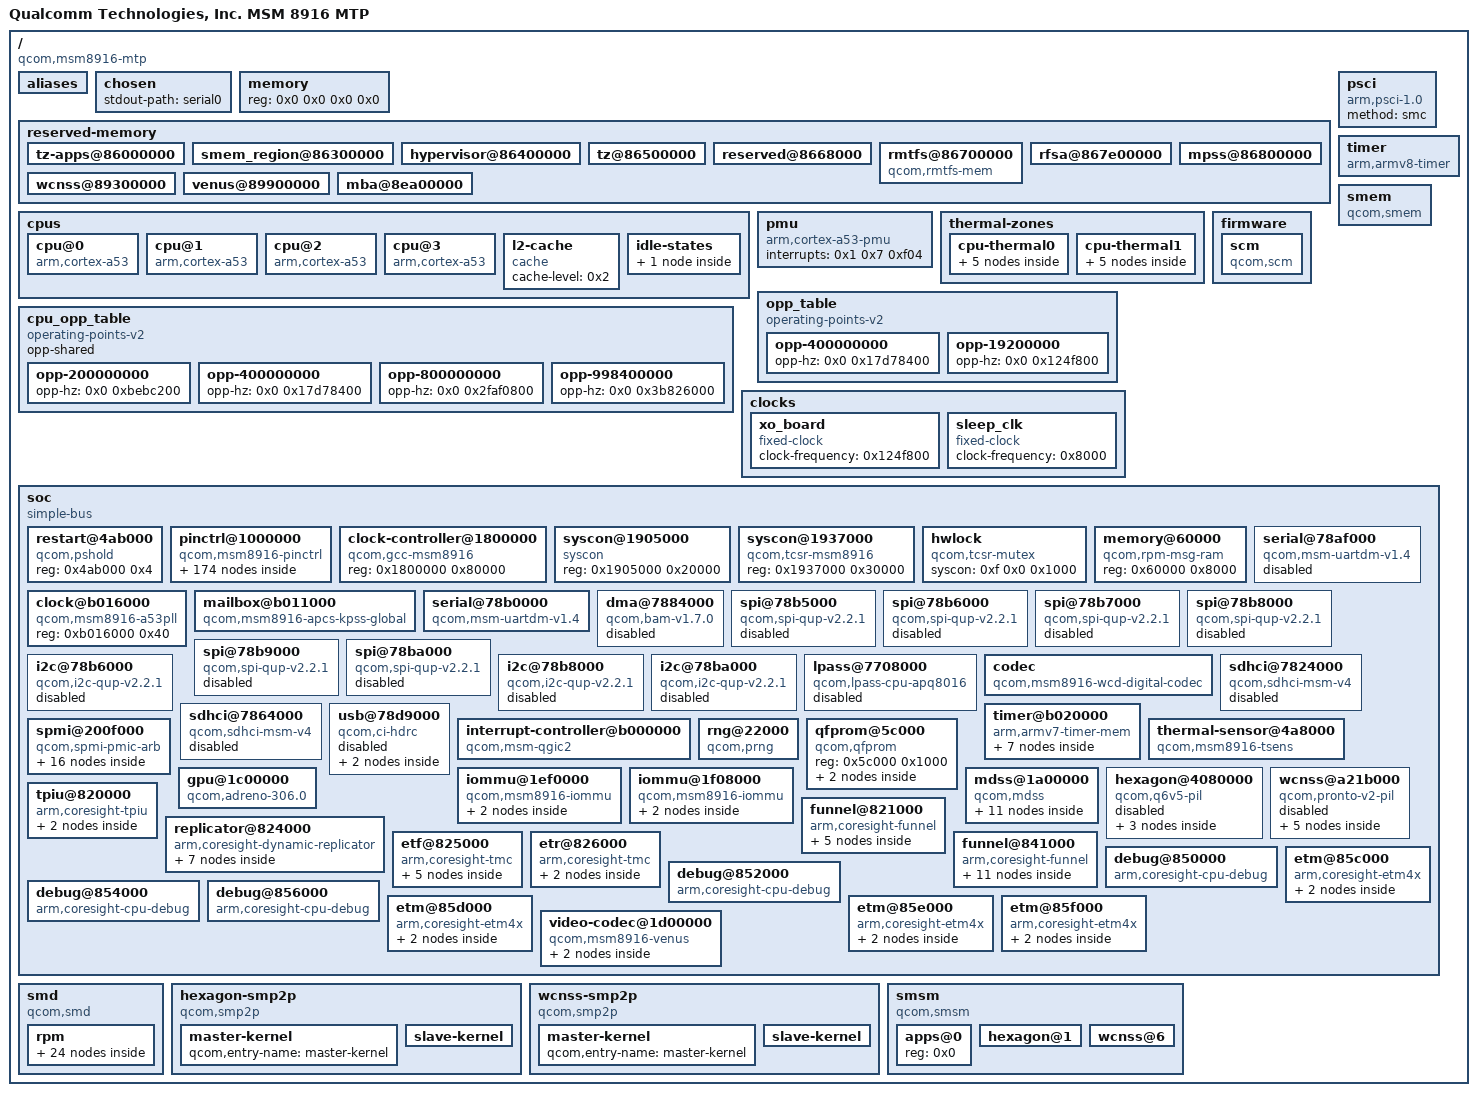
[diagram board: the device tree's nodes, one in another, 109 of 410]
/dts-v1/;

/ {
	model = "Qualcomm Technologies, Inc. MSM 8916 MTP";
	compatible = "qcom,msm8916-mtp", "qcom,msm8916-mtp/1", "qcom,msm8916", "qcom,mtp";
	interrupt-parent = <0x1>;
	#address-cells = <0x2>;
	#size-cells = <0x2>;

	aliases {
		sdhc1 = "/soc/sdhci@7824000";
		sdhc2 = "/soc/sdhci@7864000";
		serial0 = "/soc/serial@78b0000";
		usid0 = "/soc/spmi@200f000/pm8916@0";
	};

	chosen {
		stdout-path = "serial0";
	};

	memory {
		device_type = "memory";
		reg = <0x0 0x0 0x0 0x0>;
	};

	reserved-memory {
		#address-cells = <0x2>;
		#size-cells = <0x2>;
		ranges;

		tz-apps@86000000 {
			reg = <0x0 0x86000000 0x0 0x300000>;
			no-map;
		};

		smem_region@86300000 {
			reg = <0x0 0x86300000 0x0 0x100000>;
			no-map;
			phandle = <0xa>;
		};

		hypervisor@86400000 {
			reg = <0x0 0x86400000 0x0 0x100000>;
			no-map;
		};

		tz@86500000 {
			reg = <0x0 0x86500000 0x0 0x180000>;
			no-map;
		};

		reserved@8668000 {
			reg = <0x0 0x86680000 0x0 0x80000>;
			no-map;
		};

		rmtfs@86700000 {
			compatible = "qcom,rmtfs-mem";
			reg = <0x0 0x86700000 0x0 0xe0000>;
			no-map;
			qcom,client-id = <0x1>;
		};

		rfsa@867e00000 {
			reg = <0x0 0x867e0000 0x0 0x20000>;
			no-map;
		};

		mpss@86800000 {
			reg = <0x0 0x86800000 0x0 0x2b00000>;
			no-map;
			phandle = <0x3d>;
		};

		wcnss@89300000 {
			reg = <0x0 0x89300000 0x0 0x600000>;
			no-map;
			phandle = <0x3e>;
		};

		venus@89900000 {
			reg = <0x0 0x89900000 0x0 0x600000>;
			no-map;
			phandle = <0x5c>;
		};

		mba@8ea00000 {
			no-map;
			reg = <0x0 0x8ea00000 0x0 0x100000>;
			phandle = <0x3c>;
		};
	};

	cpus {
		#address-cells = <0x1>;
		#size-cells = <0x0>;

		cpu@0 {
			device_type = "cpu";
			compatible = "arm,cortex-a53", "arm,armv8";
			reg = <0x0>;
			next-level-cache = <0x2>;
			enable-method = "psci";
			cpu-idle-states = <0x3>;
			clocks = <0x4>;
			operating-points-v2 = <0x5>;
			#cooling-cells = <0x2>;
			phandle = <0x8>;
		};

		cpu@1 {
			device_type = "cpu";
			compatible = "arm,cortex-a53", "arm,armv8";
			reg = <0x1>;
			next-level-cache = <0x2>;
			enable-method = "psci";
			cpu-idle-states = <0x3>;
			clocks = <0x4>;
			operating-points-v2 = <0x5>;
			#cooling-cells = <0x2>;
			phandle = <0x55>;
		};

		cpu@2 {
			device_type = "cpu";
			compatible = "arm,cortex-a53", "arm,armv8";
			reg = <0x2>;
			next-level-cache = <0x2>;
			enable-method = "psci";
			cpu-idle-states = <0x3>;
			clocks = <0x4>;
			operating-points-v2 = <0x5>;
			#cooling-cells = <0x2>;
			phandle = <0x56>;
		};

		cpu@3 {
			device_type = "cpu";
			compatible = "arm,cortex-a53", "arm,armv8";
			reg = <0x3>;
			next-level-cache = <0x2>;
			enable-method = "psci";
			cpu-idle-states = <0x3>;
			clocks = <0x4>;
			operating-points-v2 = <0x5>;
			#cooling-cells = <0x2>;
			phandle = <0x57>;
		};

		l2-cache {
			compatible = "cache";
			cache-level = <0x2>;
			phandle = <0x2>;
		};

		idle-states {

			spc {
				compatible = "arm,idle-state";
				arm,psci-suspend-param = <0x40000002>;
				entry-latency-us = <0x82>;
				exit-latency-us = <0x96>;
				min-residency-us = <0x7d0>;
				local-timer-stop;
				phandle = <0x3>;
			};
		};
	};

	psci {
		compatible = "arm,psci-1.0";
		method = "smc";
	};

	pmu {
		compatible = "arm,cortex-a53-pmu";
		interrupts = <0x1 0x7 0xf04>;
	};

	thermal-zones {

		cpu-thermal0 {
			polling-delay-passive = <0xfa>;
			polling-delay = <0x3e8>;
			thermal-sensors = <0x6 0x4>;

			trips {

				trip0 {
					temperature = <0x124f8>;
					hysteresis = <0x7d0>;
					type = "passive";
					phandle = <0x7>;
				};

				trip1 {
					temperature = <0x1adb0>;
					hysteresis = <0x7d0>;
					type = "critical";
					phandle = <0x5d>;
				};
			};

			cooling-maps {

				map0 {
					trip = <0x7>;
					cooling-device = <0x8 0xffffffff 0xffffffff>;
				};
			};
		};

		cpu-thermal1 {
			polling-delay-passive = <0xfa>;
			polling-delay = <0x3e8>;
			thermal-sensors = <0x6 0x3>;

			trips {

				trip0 {
					temperature = <0x124f8>;
					hysteresis = <0x7d0>;
					type = "passive";
					phandle = <0x9>;
				};

				trip1 {
					temperature = <0x1adb0>;
					hysteresis = <0x7d0>;
					type = "critical";
					phandle = <0x5e>;
				};
			};

			cooling-maps {

				map0 {
					trip = <0x9>;
					cooling-device = <0x8 0xffffffff 0xffffffff>;
				};
			};
		};
	};

	cpu_opp_table {
		compatible = "operating-points-v2";
		opp-shared;
		phandle = <0x5>;

		opp-200000000 {
			opp-hz = <0x0 0xbebc200>;
		};

		opp-400000000 {
			opp-hz = <0x0 0x17d78400>;
		};

		opp-800000000 {
			opp-hz = <0x0 0x2faf0800>;
		};

		opp-998400000 {
			opp-hz = <0x0 0x3b826000>;
		};
	};

	opp_table {
		compatible = "operating-points-v2";
		phandle = <0x2f>;

		opp-400000000 {
			opp-hz = <0x0 0x17d78400>;
		};

		opp-19200000 {
			opp-hz = <0x0 0x124f800>;
		};
	};

	timer {
		compatible = "arm,armv8-timer";
		interrupts = <0x1 0x2 0xf08 0x1 0x3 0xf08 0x1 0x4 0xf08 0x1 0x1 0xf08>;
	};

	clocks {

		xo_board {
			compatible = "fixed-clock";
			#clock-cells = <0x0>;
			clock-frequency = <0x124f800>;
			phandle = <0x26>;
		};

		sleep_clk {
			compatible = "fixed-clock";
			#clock-cells = <0x0>;
			clock-frequency = <0x8000>;
			phandle = <0x5f>;
		};
	};

	smem {
		compatible = "qcom,smem";
		memory-region = <0xa>;
		qcom,rpm-msg-ram = <0xb>;
		hwlocks = <0xc 0x3>;
	};

	firmware {

		scm {
			compatible = "qcom,scm";
			clocks = <0xd 0x68 0xd 0x67 0xd 0x66>;
			clock-names = "core", "bus", "iface";
			#reset-cells = <0x1>;
			qcom,dload-mode = <0xe 0x6100>;
			phandle = <0x38>;
		};
	};

	soc {
		#address-cells = <0x1>;
		#size-cells = <0x1>;
		ranges = <0x0 0x0 0x0 0xffffffff>;
		compatible = "simple-bus";
		phandle = <0x60>;

		restart@4ab000 {
			compatible = "qcom,pshold";
			reg = <0x4ab000 0x4>;
		};

		pinctrl@1000000 {
			compatible = "qcom,msm8916-pinctrl";
			reg = <0x1000000 0x300000>;
			interrupts = <0x0 0xd0 0x4>;
			gpio-controller;
			#gpio-cells = <0x2>;
			interrupt-controller;
			#interrupt-cells = <0x2>;
			phandle = <0x61>;

			blsp1_uart1_default {
				phandle = <0x62>;

				pinmux {
					function = "blsp_uart1";
					pins = "gpio0", "gpio1", "gpio2", "gpio3";
				};

				pinconf {
					pins = "gpio0", "gpio1", "gpio2", "gpio3";
					drive-strength = <0x10>;
					bias-disable;
				};
			};

			blsp1_uart1_sleep {
				phandle = <0x63>;

				pinmux {
					function = "gpio";
					pins = "gpio0", "gpio1", "gpio2", "gpio3";
				};

				pinconf {
					pins = "gpio0", "gpio1", "gpio2", "gpio3";
					drive-strength = <0x2>;
					bias-pull-down;
				};
			};

			blsp1_uart2_default {
				phandle = <0x12>;

				pinmux {
					function = "blsp_uart2";
					pins = "gpio4", "gpio5";
				};

				pinconf {
					pins = "gpio4", "gpio5";
					drive-strength = <0x10>;
					bias-disable;
				};
			};

			blsp1_uart2_sleep {
				phandle = <0x13>;

				pinmux {
					function = "gpio";
					pins = "gpio4", "gpio5";
				};

				pinconf {
					pins = "gpio4", "gpio5";
					drive-strength = <0x2>;
					bias-pull-down;
				};
			};

			spi1_default {
				phandle = <0x14>;

				pinmux {
					function = "blsp_spi1";
					pins = "gpio0", "gpio1", "gpio3";
				};

				pinmux_cs {
					function = "gpio";
					pins = "gpio2";
				};

				pinconf {
					pins = "gpio0", "gpio1", "gpio3";
					drive-strength = <0xc>;
					bias-disable;
				};

				pinconf_cs {
					pins = "gpio2";
					drive-strength = <0x10>;
					bias-disable;
					output-high;
				};
			};

			spi1_sleep {
				phandle = <0x15>;

				pinmux {
					function = "gpio";
					pins = "gpio0", "gpio1", "gpio2", "gpio3";
				};

				pinconf {
					pins = "gpio0", "gpio1", "gpio2", "gpio3";
					drive-strength = <0x2>;
					bias-pull-down;
				};
			};

			spi2_default {
				phandle = <0x16>;

				pinmux {
					function = "blsp_spi2";
					pins = "gpio4", "gpio5", "gpio7";
				};

				pinmux_cs {
					function = "gpio";
					pins = "gpio6";
				};

				pinconf {
					pins = "gpio4", "gpio5", "gpio7";
					drive-strength = <0xc>;
					bias-disable;
				};

				pinconf_cs {
					pins = "gpio6";
					drive-strength = <0x10>;
					bias-disable;
					output-high;
				};
			};

			spi2_sleep {
				phandle = <0x17>;

				pinmux {
					function = "gpio";
					pins = "gpio4", "gpio5", "gpio6", "gpio7";
				};

				pinconf {
					pins = "gpio4", "gpio5", "gpio6", "gpio7";
					drive-strength = <0x2>;
					bias-pull-down;
				};
			};

			spi3_default {
				phandle = <0x18>;

				pinmux {
					function = "blsp_spi3";
					pins = "gpio8", "gpio9", "gpio11";
				};

				pinmux_cs {
					function = "gpio";
					pins = "gpio10";
				};

				pinconf {
					pins = "gpio8", "gpio9", "gpio11";
					drive-strength = <0xc>;
					bias-disable;
				};

				pinconf_cs {
					pins = "gpio10";
					drive-strength = <0x10>;
					bias-disable;
					output-high;
				};
			};

			spi3_sleep {
				phandle = <0x19>;

				pinmux {
					function = "gpio";
					pins = "gpio8", "gpio9", "gpio10", "gpio11";
				};

				pinconf {
					pins = "gpio8", "gpio9", "gpio10", "gpio11";
					drive-strength = <0x2>;
					bias-pull-down;
				};
			};

			spi4_default {
				phandle = <0x1a>;

				pinmux {
					function = "blsp_spi4";
					pins = "gpio12", "gpio13", "gpio15";
				};

				pinmux_cs {
					function = "gpio";
					pins = "gpio14";
				};

				pinconf {
					pins = "gpio12", "gpio13", "gpio15";
					drive-strength = <0xc>;
					bias-disable;
				};

				pinconf_cs {
					pins = "gpio14";
					drive-strength = <0x10>;
					bias-disable;
					output-high;
				};
			};

			spi4_sleep {
				phandle = <0x1b>;

				pinmux {
					function = "gpio";
					pins = "gpio12", "gpio13", "gpio14", "gpio15";
				};

				pinconf {
					pins = "gpio12", "gpio13", "gpio14", "gpio15";
					drive-strength = <0x2>;
					bias-pull-down;
				};
			};

			spi5_default {
				phandle = <0x1c>;

				pinmux {
					function = "blsp_spi5";
					pins = "gpio16", "gpio17", "gpio19";
				};

				pinmux_cs {
					function = "gpio";
					pins = "gpio18";
				};

				pinconf {
					pins = "gpio16", "gpio17", "gpio19";
					drive-strength = <0xc>;
					bias-disable;
				};

				pinconf_cs {
					pins = "gpio18";
					drive-strength = <0x10>;
					bias-disable;
					output-high;
				};
			};

			spi5_sleep {
				phandle = <0x1d>;

				pinmux {
					function = "gpio";
					pins = "gpio16", "gpio17", "gpio18", "gpio19";
				};

				pinconf {
					pins = "gpio16", "gpio17", "gpio18", "gpio19";
					drive-strength = <0x2>;
					bias-pull-down;
				};
			};

			spi6_default {
				phandle = <0x1e>;

				pinmux {
					function = "blsp_spi6";
					pins = "gpio20", "gpio21", "gpio23";
				};

				pinmux_cs {
					function = "gpio";
					pins = "gpio22";
				};

				pinconf {
					pins = "gpio20", "gpio21", "gpio23";
					drive-strength = <0xc>;
					bias-disable;
				};

				pinconf_cs {
					pins = "gpio22";
					drive-strength = <0x10>;
					bias-disable;
					output-high;
				};
			};

			spi6_sleep {
				phandle = <0x1f>;

				pinmux {
					function = "gpio";
					pins = "gpio20", "gpio21", "gpio22", "gpio23";
				};

				pinconf {
					pins = "gpio20", "gpio21", "gpio22", "gpio23";
					drive-strength = <0x2>;
					bias-pull-down;
				};
			};

			i2c2_default {
				phandle = <0x20>;

				pinmux {
					function = "blsp_i2c2";
					pins = "gpio6", "gpio7";
				};

				pinconf {
					pins = "gpio6", "gpio7";
					drive-strength = <0x10>;
					bias-disable;
				};
			};

			i2c2_sleep {
				phandle = <0x21>;

				pinmux {
					function = "gpio";
					pins = "gpio6", "gpio7";
				};

				pinconf {
					pins = "gpio6", "gpio7";
					drive-strength = <0x2>;
					bias-disable;
				};
			};

			i2c4_default {
				phandle = <0x22>;

				pinmux {
					function = "blsp_i2c4";
					pins = "gpio14", "gpio15";
				};

				pinconf {
					pins = "gpio14", "gpio15";
					drive-strength = <0x10>;
					bias-disable;
				};
			};

			i2c4_sleep {
				phandle = <0x23>;

				pinmux {
					function = "gpio";
					pins = "gpio14", "gpio15";
				};

				pinconf {
					pins = "gpio14", "gpio15";
					drive-strength = <0x2>;
					bias-disable;
				};
			};

			i2c6_default {
				phandle = <0x24>;

				pinmux {
					function = "blsp_i2c6";
					pins = "gpio22", "gpio23";
				};

				pinconf {
					pins = "gpio22", "gpio23";
					drive-strength = <0x10>;
					bias-disable;
				};
			};

			i2c6_sleep {
				phandle = <0x25>;

				pinmux {
					function = "gpio";
					pins = "gpio22", "gpio23";
				};

				pinconf {
					pins = "gpio22", "gpio23";
					drive-strength = <0x2>;
					bias-disable;
				};
			};

			pmx_sdc1_clk {

				clk_on {
					phandle = <0x64>;

					pinmux {
						pins = "sdc1_clk";
					};

					pinconf {
						pins = "sdc1_clk";
						bias-disable;
						drive-strength = <0x10>;
					};
				};

				clk_off {
					phandle = <0x65>;

					pinmux {
						pins = "sdc1_clk";
					};

					pinconf {
						pins = "sdc1_clk";
						bias-disable;
						drive-strength = <0x2>;
					};
				};
			};

			pmx_sdc1_cmd {

				cmd_on {
					phandle = <0x66>;

					pinmux {
						pins = "sdc1_cmd";
					};

					pinconf {
						pins = "sdc1_cmd";
						bias-pull-up;
						drive-strength = <0xa>;
					};
				};

				cmd_off {
					phandle = <0x67>;

					pinmux {
						pins = "sdc1_cmd";
					};

					pinconf {
						pins = "sdc1_cmd";
						bias-pull-up;
						drive-strength = <0x2>;
					};
				};
			};

			pmx_sdc1_data {

				data_on {
					phandle = <0x68>;

					pinmux {
						pins = "sdc1_data";
					};

					pinconf {
						pins = "sdc1_data";
						bias-pull-up;
						drive-strength = <0xa>;
					};
				};

				data_off {
					phandle = <0x69>;

					pinmux {
						pins = "sdc1_data";
					};

					pinconf {
						pins = "sdc1_data";
						bias-pull-up;
						drive-strength = <0x2>;
					};
				};
			};

			pmx_sdc2_clk {

				clk_on {
					phandle = <0x6a>;

					pinmux {
						pins = "sdc2_clk";
					};

					pinconf {
						pins = "sdc2_clk";
						bias-disable;
						drive-strength = <0x10>;
					};
				};

				clk_off {
					phandle = <0x6b>;

					pinmux {
						pins = "sdc2_clk";
					};

					pinconf {
						pins = "sdc2_clk";
						bias-disable;
						drive-strength = <0x2>;
					};
				};
			};

			pmx_sdc2_cmd {

				cmd_on {
					phandle = <0x6c>;

					pinmux {
						pins = "sdc2_cmd";
					};

					pinconf {
						pins = "sdc2_cmd";
						bias-pull-up;
						drive-strength = <0xa>;
					};
				};

				cmd_off {
					phandle = <0x6d>;

					pinmux {
						pins = "sdc2_cmd";
					};

					pinconf {
						pins = "sdc2_cmd";
						bias-pull-up;
						drive-strength = <0x2>;
					};
				};
			};

			pmx_sdc2_data {

				data_on {
					phandle = <0x6e>;

					pinmux {
						pins = "sdc2_data";
					};

					pinconf {
						pins = "sdc2_data";
						bias-pull-up;
						drive-strength = <0xa>;
					};
				};

				data_off {
					phandle = <0x6f>;

					pinmux {
						pins = "sdc2_data";
					};

					pinconf {
						pins = "sdc2_data";
						bias-pull-up;
						drive-strength = <0x2>;
					};
				};
			};

			pmx_sdc2_cd_pin {

				cd_on {
					phandle = <0x70>;

					pinmux {
						function = "gpio";
						pins = "gpio38";
					};

					pinconf {
						pins = "gpio38";
						drive-strength = <0x2>;
						bias-pull-up;
					};
				};

				cd_off {
					phandle = <0x71>;

					pinmux {
						function = "gpio";
						pins = "gpio38";
					};

					pinconf {
						pins = "gpio38";
						drive-strength = <0x2>;
						bias-disable;
					};
				};
			};

			cdc-pdm-lines {

				pdm_lines_on {
					phandle = <0x72>;

					pinmux {
						function = "cdc_pdm0";
						pins = "gpio63", "gpio64", "gpio65", "gpio66", "gpio67", "gpio68";
					};

					pinconf {
						pins = "gpio63", "gpio64", "gpio65", "gpio66", "gpio67", "gpio68";
						drive-strength = <0x8>;
						bias-disable;
					};
				};

				pdm_lines_off {
					phandle = <0x73>;

					pinmux {
						function = "cdc_pdm0";
						pins = "gpio63", "gpio64", "gpio65", "gpio66", "gpio67", "gpio68";
					};

					pinconf {
						pins = "gpio63", "gpio64", "gpio65", "gpio66", "gpio67", "gpio68";
						drive-strength = <0x2>;
						bias-pull-down;
					};
				};
			};

			ext-pri-tlmm-lines {

				ext_pa_on {
					phandle = <0x74>;

					pinmux {
						function = "pri_mi2s";
						pins = "gpio113", "gpio114", "gpio115", "gpio116";
					};

					pinconf {
						pins = "gpio113", "gpio114", "gpio115", "gpio116";
						drive-strength = <0x8>;
						bias-disable;
					};
				};

				ext_pa_off {
					phandle = <0x75>;

					pinmux {
						function = "pri_mi2s";
						pins = "gpio113", "gpio114", "gpio115", "gpio116";
					};

					pinconf {
						pins = "gpio113", "gpio114", "gpio115", "gpio116";
						drive-strength = <0x2>;
						bias-disable;
					};
				};
			};

			ext-pri-ws-line {

				ext_pa_on {
					phandle = <0x76>;

					pinmux {
						function = "pri_mi2s_ws";
						pins = "gpio110";
					};

					pinconf {
						pins = "gpio110";
						drive-strength = <0x8>;
						bias-disable;
					};
				};

				ext_pa_off {
					phandle = <0x77>;

					pinmux {
						function = "pri_mi2s_ws";
						pins = "gpio110";
					};

					pinconf {
						pins = "gpio110";
						drive-strength = <0x2>;
						bias-disable;
					};
				};
			};

			ext-mclk-tlmm-lines {

				mclk_lines_on {
					phandle = <0x78>;

					pinmux {
						function = "pri_mi2s";
						pins = "gpio116";
					};

					pinconf {
						pins = "gpio116";
						drive-strength = <0x8>;
						bias-disable;
					};
				};

				mclk_lines_off {
					phandle = <0x79>;

					pinmux {
						function = "pri_mi2s";
						pins = "gpio116";
					};

					pinconf {
						pins = "gpio116";
						drive-strength = <0x2>;
						bias-disable;
					};
				};
			};

			ext-sec-tlmm-lines {

				tlmm_lines_on {
					phandle = <0x7a>;

					pinmux {
						function = "sec_mi2s";
						pins = "gpio112", "gpio117", "gpio118", "gpio119";
					};

					pinconf {
						pins = "gpio112", "gpio117", "gpio118", "gpio119";
						drive-strength = <0x8>;
						bias-disable;
					};
				};

				tlmm_lines_off {
					phandle = <0x7b>;

					pinmux {
						function = "sec_mi2s";
						pins = "gpio112", "gpio117", "gpio118", "gpio119";
					};

					pinconf {
						pins = "gpio112", "gpio117", "gpio118", "gpio119";
						drive-strength = <0x2>;
						bias-disable;
					};
				};
			};

			cdc-dmic-lines {

				dmic_lines_on {
					phandle = <0x7c>;

					pinmux_dmic0_clk {
						function = "dmic0_clk";
						pins = "gpio0";
					};

					pinmux_dmic0_data {
						function = "dmic0_data";
						pins = "gpio1";
					};

					pinconf {
						pins = "gpio0", "gpio1";
						drive-strength = <0x8>;
					};
				};

				dmic_lines_off {
					phandle = <0x7d>;

					pinmux_dmic0_clk {
						function = "dmic0_clk";
						pins = "gpio0";
					};

					pinmux_dmic0_data {
						function = "dmic0_data";
						pins = "gpio1";
					};

					pinconf {
						pins = "gpio0", "gpio1";
						drive-strength = <0x2>;
						bias-disable;
					};
				};
			};

			wcnss-active {
				phandle = <0x41>;

				pinmux {
					pins = "gpio40", "gpio41", "gpio42", "gpio43", "gpio44";
					function = "wcss_wlan";
				};

				pinconf {
					pins = "gpio40", "gpio41", "gpio42", "gpio43", "gpio44";
					drive-strength = <0x6>;
					bias-pull-up;
				};
			};
		};

		clock-controller@1800000 {
			compatible = "qcom,gcc-msm8916";
			#clock-cells = <0x1>;
			#reset-cells = <0x1>;
			#power-domain-cells = <0x1>;
			reg = <0x1800000 0x80000>;
			phandle = <0xd>;
		};

		syscon@1905000 {
			compatible = "syscon";
			reg = <0x1905000 0x20000>;
			phandle = <0xf>;
		};

		syscon@1937000 {
			compatible = "qcom,tcsr-msm8916", "syscon";
			reg = <0x1937000 0x30000>;
			phandle = <0xe>;
		};

		hwlock {
			compatible = "qcom,tcsr-mutex";
			syscon = <0xf 0x0 0x1000>;
			#hwlock-cells = <0x1>;
			phandle = <0xc>;
		};

		memory@60000 {
			compatible = "qcom,rpm-msg-ram";
			reg = <0x60000 0x8000>;
			phandle = <0xb>;
		};

		serial@78af000 {
			compatible = "qcom,msm-uartdm-v1.4", "qcom,msm-uartdm";
			reg = <0x78af000 0x200>;
			interrupts = <0x0 0x6b 0x4>;
			clocks = <0xd 0x44 0xd 0x36>;
			clock-names = "core", "iface";
			dmas = <0x10 0x1 0x10 0x0>;
			dma-names = "rx", "tx";
			status = "disabled";
			phandle = <0x7e>;
		};

		clock@b016000 {
			compatible = "qcom,msm8916-a53pll";
			reg = <0xb016000 0x40>;
			#clock-cells = <0x0>;
			phandle = <0x11>;
		};

		mailbox@b011000 {
			compatible = "qcom,msm8916-apcs-kpss-global", "syscon";
			reg = <0xb011000 0x1000>;
			#mbox-cells = <0x1>;
			clocks = <0x11>;
			#clock-cells = <0x0>;
			phandle = <0x4>;
		};

		serial@78b0000 {
			compatible = "qcom,msm-uartdm-v1.4", "qcom,msm-uartdm";
			reg = <0x78b0000 0x200>;
			interrupts = <0x0 0x6c 0x4>;
			clocks = <0xd 0x45 0xd 0x36>;
			clock-names = "core", "iface";
			dmas = <0x10 0x3 0x10 0x2>;
			dma-names = "rx", "tx";
			status = "okay";
			pinctrl-names = "default", "sleep";
			pinctrl-0 = <0x12>;
			pinctrl-1 = <0x13>;
			phandle = <0x7f>;
		};

		dma@7884000 {
			compatible = "qcom,bam-v1.7.0";
			reg = <0x7884000 0x23000>;
			interrupts = <0x0 0xee 0x4>;
			clocks = <0xd 0x36>;
			clock-names = "bam_clk";
			#dma-cells = <0x1>;
			qcom,ee = <0x0>;
			status = "disabled";
			phandle = <0x10>;
		};

		spi@78b5000 {
			compatible = "qcom,spi-qup-v2.2.1";
			reg = <0x78b5000 0x500>;
			interrupts = <0x0 0x5f 0x4>;
			clocks = <0xd 0x39 0xd 0x36>;
			clock-names = "core", "iface";
			dmas = <0x10 0x5 0x10 0x4>;
			dma-names = "rx", "tx";
			pinctrl-names = "default", "sleep";
			pinctrl-0 = <0x14>;
			pinctrl-1 = <0x15>;
			#address-cells = <0x1>;
			#size-cells = <0x0>;
			status = "disabled";
			phandle = <0x80>;
		};

		spi@78b6000 {
			compatible = "qcom,spi-qup-v2.2.1";
			reg = <0x78b6000 0x500>;
			interrupts = <0x0 0x60 0x4>;
			clocks = <0xd 0x3b 0xd 0x36>;
			clock-names = "core", "iface";
			dmas = <0x10 0x7 0x10 0x6>;
			dma-names = "rx", "tx";
			pinctrl-names = "default", "sleep";
			pinctrl-0 = <0x16>;
			pinctrl-1 = <0x17>;
			#address-cells = <0x1>;
			#size-cells = <0x0>;
			status = "disabled";
			phandle = <0x81>;
		};

		spi@78b7000 {
			compatible = "qcom,spi-qup-v2.2.1";
			reg = <0x78b7000 0x500>;
			interrupts = <0x0 0x61 0x4>;
			clocks = <0xd 0x3d 0xd 0x36>;
			clock-names = "core", "iface";
			dmas = <0x10 0x9 0x10 0x8>;
			dma-names = "rx", "tx";
			pinctrl-names = "default", "sleep";
			pinctrl-0 = <0x18>;
			pinctrl-1 = <0x19>;
			#address-cells = <0x1>;
			#size-cells = <0x0>;
			status = "disabled";
			phandle = <0x82>;
		};

		spi@78b8000 {
			compatible = "qcom,spi-qup-v2.2.1";
			reg = <0x78b8000 0x500>;
			interrupts = <0x0 0x62 0x4>;
			clocks = <0xd 0x3f 0xd 0x36>;
			clock-names = "core", "iface";
			dmas = <0x10 0xb 0x10 0xa>;
			dma-names = "rx", "tx";
			pinctrl-names = "default", "sleep";
			pinctrl-0 = <0x1a>;
			pinctrl-1 = <0x1b>;
			#address-cells = <0x1>;
			#size-cells = <0x0>;
			status = "disabled";
			phandle = <0x83>;
		};

		spi@78b9000 {
			compatible = "qcom,spi-qup-v2.2.1";
			reg = <0x78b9000 0x500>;
			interrupts = <0x0 0x63 0x4>;
			clocks = <0xd 0x41 0xd 0x36>;
			clock-names = "core", "iface";
			dmas = <0x10 0xd 0x10 0xc>;
			dma-names = "rx", "tx";
			pinctrl-names = "default", "sleep";
			pinctrl-0 = <0x1c>;
			pinctrl-1 = <0x1d>;
			#address-cells = <0x1>;
			#size-cells = <0x0>;
			status = "disabled";
			phandle = <0x84>;
		};

		spi@78ba000 {
			compatible = "qcom,spi-qup-v2.2.1";
			reg = <0x78ba000 0x500>;
			interrupts = <0x0 0x64 0x4>;
			clocks = <0xd 0x43 0xd 0x36>;
			clock-names = "core", "iface";
			dmas = <0x10 0xf 0x10 0xe>;
			dma-names = "rx", "tx";
			pinctrl-names = "default", "sleep";
			pinctrl-0 = <0x1e>;
			pinctrl-1 = <0x1f>;
			#address-cells = <0x1>;
			#size-cells = <0x0>;
			status = "disabled";
			phandle = <0x85>;
		};

		i2c@78b6000 {
			compatible = "qcom,i2c-qup-v2.2.1";
			reg = <0x78b6000 0x500>;
			interrupts = <0x0 0x60 0x4>;
			clocks = <0xd 0x36 0xd 0x3a>;
			clock-names = "iface", "core";
			pinctrl-names = "default", "sleep";
			pinctrl-0 = <0x20>;
			pinctrl-1 = <0x21>;
			#address-cells = <0x1>;
			#size-cells = <0x0>;
			status = "disabled";
			phandle = <0x86>;
		};

		i2c@78b8000 {
			compatible = "qcom,i2c-qup-v2.2.1";
			reg = <0x78b8000 0x500>;
			interrupts = <0x0 0x62 0x4>;
			clocks = <0xd 0x36 0xd 0x3e>;
			clock-names = "iface", "core";
			pinctrl-names = "default", "sleep";
			pinctrl-0 = <0x22>;
			pinctrl-1 = <0x23>;
			#address-cells = <0x1>;
			#size-cells = <0x0>;
			status = "disabled";
			phandle = <0x87>;
		};

		i2c@78ba000 {
			compatible = "qcom,i2c-qup-v2.2.1";
			reg = <0x78ba000 0x500>;
			interrupts = <0x0 0x64 0x4>;
			clocks = <0xd 0x36 0xd 0x42>;
			clock-names = "iface", "core";
			pinctrl-names = "default", "sleep";
			pinctrl-0 = <0x24>;
			pinctrl-1 = <0x25>;
			#address-cells = <0x1>;
			#size-cells = <0x0>;
			status = "disabled";
			phandle = <0x88>;
		};

		lpass@7708000 {
			status = "disabled";
			compatible = "qcom,lpass-cpu-apq8016";
			clocks = <0xd 0x9a 0xd 0x96 0xd 0x97 0xd 0x9c 0xd 0x9d 0xd 0x9d 0xd 0x9e>;
			clock-names = "ahbix-clk", "pcnoc-mport-clk", "pcnoc-sway-clk", "mi2s-bit-clk0", "mi2s-bit-clk1", "mi2s-bit-clk2", "mi2s-bit-clk3";
			#sound-dai-cells = <0x1>;
			interrupts = <0x0 0xa0 0x4>;
			interrupt-names = "lpass-irq-lpaif";
			reg = <0x7708000 0x10000>;
			reg-names = "lpass-lpaif";
			phandle = <0x89>;
		};

		codec {
			compatible = "qcom,msm8916-wcd-digital-codec";
			reg = <0x771c000 0x400>;
			clocks = <0xd 0x9a 0xd 0x9f>;
			clock-names = "ahbix-clk", "mclk";
			#sound-dai-cells = <0x1>;
			phandle = <0x8a>;
		};

		sdhci@7824000 {
			compatible = "qcom,sdhci-msm-v4";
			reg = <0x7824900 0x11c 0x7824000 0x800>;
			reg-names = "hc_mem", "core_mem";
			interrupts = <0x0 0x7b 0x4 0x0 0x8a 0x4>;
			interrupt-names = "hc_irq", "pwr_irq";
			clocks = <0xd 0x7b 0xd 0x7a 0x26>;
			clock-names = "core", "iface", "xo";
			mmc-ddr-1_8v;
			bus-width = <0x8>;
			non-removable;
			status = "disabled";
			phandle = <0x8b>;
		};

		sdhci@7864000 {
			compatible = "qcom,sdhci-msm-v4";
			reg = <0x7864900 0x11c 0x7864000 0x800>;
			reg-names = "hc_mem", "core_mem";
			interrupts = <0x0 0x7d 0x4 0x0 0xdd 0x4>;
			interrupt-names = "hc_irq", "pwr_irq";
			clocks = <0xd 0x7d 0xd 0x7c 0x26>;
			clock-names = "core", "iface", "xo";
			bus-width = <0x4>;
			status = "disabled";
			phandle = <0x8c>;
		};

		usb@78d9000 {
			compatible = "qcom,ci-hdrc";
			reg = <0x78d9000 0x200 0x78d9200 0x200>;
			interrupts = <0x0 0x86 0x4 0x0 0x8c 0x4>;
			clocks = <0xd 0x85 0xd 0x86>;
			clock-names = "iface", "core";
			assigned-clocks = <0xd 0x86>;
			assigned-clock-rates = <0x4c4b400>;
			resets = <0xd 0x22>;
			reset-names = "core";
			phy_type = "ulpi";
			dr_mode = "otg";
			ahb-burst-config = <0x0>;
			phy-names = "usb-phy";
			phys = <0x27>;
			status = "disabled";
			#reset-cells = <0x1>;
			phandle = <0x28>;

			ulpi {

				phy {
					compatible = "qcom,usb-hs-phy-msm8916", "qcom,usb-hs-phy";
					#phy-cells = <0x0>;
					clocks = <0x26 0xd 0x84>;
					clock-names = "ref", "sleep";
					resets = <0xd 0x23 0x28 0x0>;
					reset-names = "phy", "por";
					qcom,init-seq = <0x44016b 0x2240313>;
					phandle = <0x27>;
				};
			};
		};

		interrupt-controller@b000000 {
			compatible = "qcom,msm-qgic2";
			interrupt-controller;
			#interrupt-cells = <0x3>;
			reg = <0xb000000 0x1000 0xb002000 0x1000>;
			phandle = <0x1>;
		};

		timer@b020000 {
			#address-cells = <0x1>;
			#size-cells = <0x1>;
			ranges;
			compatible = "arm,armv7-timer-mem";
			reg = <0xb020000 0x1000>;
			clock-frequency = <0x124f800>;

			frame@b021000 {
				frame-number = <0x0>;
				interrupts = <0x0 0x8 0x4 0x0 0x7 0x4>;
				reg = <0xb021000 0x1000 0xb022000 0x1000>;
			};

			frame@b023000 {
				frame-number = <0x1>;
				interrupts = <0x0 0x9 0x4>;
				reg = <0xb023000 0x1000>;
				status = "disabled";
			};

			frame@b024000 {
				frame-number = <0x2>;
				interrupts = <0x0 0xa 0x4>;
				reg = <0xb024000 0x1000>;
				status = "disabled";
			};

			frame@b025000 {
				frame-number = <0x3>;
				interrupts = <0x0 0xb 0x4>;
				reg = <0xb025000 0x1000>;
				status = "disabled";
			};

			frame@b026000 {
				frame-number = <0x4>;
				interrupts = <0x0 0xc 0x4>;
				reg = <0xb026000 0x1000>;
				status = "disabled";
			};

			frame@b027000 {
				frame-number = <0x5>;
				interrupts = <0x0 0xd 0x4>;
				reg = <0xb027000 0x1000>;
				status = "disabled";
			};

			frame@b028000 {
				frame-number = <0x6>;
				interrupts = <0x0 0xe 0x4>;
				reg = <0xb028000 0x1000>;
				status = "disabled";
			};
		};

		spmi@200f000 {
			compatible = "qcom,spmi-pmic-arb";
			reg = <0x200f000 0x1000 0x2400000 0x400000 0x2c00000 0x400000 0x3800000 0x200000 0x200a000 0x2100>;
			reg-names = "core", "chnls", "obsrvr", "intr", "cnfg";
			interrupt-names = "periph_irq";
			interrupts = <0x0 0xbe 0x4>;
			qcom,ee = <0x0>;
			qcom,channel = <0x0>;
			#address-cells = <0x2>;
			#size-cells = <0x0>;
			interrupt-controller;
			#interrupt-cells = <0x4>;
			phandle = <0x2a>;

			pm8916@0 {
				compatible = "qcom,pm8916", "qcom,spmi-pmic";
				reg = <0x0 0x0>;
				#address-cells = <0x1>;
				#size-cells = <0x0>;
				phandle = <0x8d>;

				rtc@6000 {
					compatible = "qcom,pm8941-rtc";
					reg = <0x6000>;
					reg-names = "rtc", "alarm";
					interrupts = <0x0 0x61 0x1 0x1>;
				};

				pwrkey@800 {
					compatible = "qcom,pm8941-pwrkey";
					reg = <0x800>;
					interrupts = <0x0 0x8 0x0 0x3>;
					debounce = <0x3d09>;
					bias-pull-up;
				};

				gpios@c000 {
					compatible = "qcom,pm8916-gpio";
					reg = <0xc000>;
					gpio-controller;
					#gpio-cells = <0x2>;
					interrupts = <0x0 0xc0 0x0 0x0 0x0 0xc1 0x0 0x0 0x0 0xc2 0x0 0x0 0x0 0xc3 0x0 0x0>;
					phandle = <0x8e>;
				};

				mpps@a000 {
					compatible = "qcom,pm8916-mpp";
					reg = <0xa000>;
					gpio-controller;
					#gpio-cells = <0x2>;
					interrupts = <0x0 0xa0 0x0 0x0 0x0 0xa1 0x0 0x0 0x0 0xa2 0x0 0x0 0x0 0xa3 0x0 0x0>;
					phandle = <0x8f>;
				};

				temp-alarm@2400 {
					compatible = "qcom,spmi-temp-alarm";
					reg = <0x2400>;
					interrupts = <0x0 0x24 0x0 0x1>;
					io-channels = <0x29 0x8>;
					io-channel-names = "thermal";
					#thermal-sensor-cells = <0x0>;
					phandle = <0x90>;
				};

				vadc@3100 {
					compatible = "qcom,spmi-vadc";
					reg = <0x3100>;
					interrupts = <0x0 0x31 0x0 0x1>;
					#address-cells = <0x1>;
					#size-cells = <0x0>;
					#io-channel-cells = <0x1>;
					phandle = <0x29>;

					usb_in {
						reg = <0x0>;
						qcom,pre-scaling = <0x1 0xa>;
					};

					vph_pwr {
						reg = <0x7>;
						qcom,pre-scaling = <0x1 0x3>;
					};

					die_temp {
						reg = <0x8>;
					};

					ref_625mv {
						reg = <0x9>;
					};

					ref_1250v {
						reg = <0xa>;
					};

					ref_gnd {
						reg = <0xe>;
					};

					ref_vdd {
						reg = <0xf>;
					};
				};
			};

			pm8916@1 {
				compatible = "qcom,pm8916", "qcom,spmi-pmic";
				reg = <0x1 0x0>;
				#address-cells = <0x1>;
				#size-cells = <0x0>;
				phandle = <0x91>;

				codec@f000 {
					compatible = "qcom,pm8916-wcd-analog-codec";
					reg = <0xf000>;
					reg-names = "pmic-codec-core";
					clocks = <0xd 0x9f>;
					clock-names = "mclk";
					interrupt-parent = <0x2a>;
					interrupts = <0x1 0xf0 0x0 0x0 0x1 0xf0 0x1 0x0 0x1 0xf0 0x2 0x0 0x1 0xf0 0x3 0x0 0x1 0xf0 0x4 0x0 0x1 0xf0 0x5 0x0 0x1 0xf0 0x6 0x0 0x1 0xf0 0x7 0x0 0x1 0xf1 0x0 0x0 0x1 0xf1 0x1 0x0 0x1 0xf1 0x2 0x0 0x1 0xf1 0x3 0x0 0x1 0xf1 0x4 0x0 0x1 0xf1 0x5 0x0>;
					interrupt-names = "cdc_spk_cnp_int", "cdc_spk_clip_int", "cdc_spk_ocp_int", "mbhc_ins_rem_det1", "mbhc_but_rel_det", "mbhc_but_press_det", "mbhc_ins_rem_det", "mbhc_switch_int", "cdc_ear_ocp_int", "cdc_hphr_ocp_int", "cdc_hphl_ocp_det", "cdc_ear_cnp_int", "cdc_hphr_cnp_int", "cdc_hphl_cnp_int";
					vdd-cdc-io-supply = <0x2b>;
					vdd-cdc-tx-rx-cx-supply = <0x2b>;
					vdd-micbias-supply = <0x2c>;
					#sound-dai-cells = <0x1>;
					phandle = <0x92>;
				};
			};
		};

		rng@22000 {
			compatible = "qcom,prng";
			reg = <0x22000 0x200>;
			clocks = <0xd 0x79>;
			clock-names = "core";
		};

		qfprom@5c000 {
			compatible = "qcom,qfprom";
			reg = <0x5c000 0x1000>;
			#address-cells = <0x1>;
			#size-cells = <0x1>;
			phandle = <0x93>;

			caldata@d0 {
				reg = <0xd0 0x8>;
				phandle = <0x2d>;
			};

			calsel@ec {
				reg = <0xec 0x4>;
				phandle = <0x2e>;
			};
		};

		thermal-sensor@4a8000 {
			compatible = "qcom,msm8916-tsens";
			reg = <0x4a8000 0x2000>;
			nvmem-cells = <0x2d 0x2e>;
			nvmem-cell-names = "calib", "calib_sel";
			#thermal-sensor-cells = <0x1>;
			phandle = <0x6>;
		};

		iommu@1ef0000 {
			#address-cells = <0x1>;
			#size-cells = <0x1>;
			#iommu-cells = <0x1>;
			compatible = "qcom,msm8916-iommu", "qcom,msm-iommu-v1";
			ranges = <0x0 0x1e20000 0x40000>;
			reg = <0x1ef0000 0x3000>;
			clocks = <0xd 0x81 0xd 0x8b>;
			clock-names = "iface", "bus";
			qcom,iommu-secure-id = <0x11>;
			phandle = <0x32>;

			iommu-ctx@4000 {
				compatible = "qcom,msm-iommu-v1-ns";
				reg = <0x4000 0x1000>;
				interrupts = <0x0 0x46 0x4>;
			};

			iommu-ctx@5000 {
				compatible = "qcom,msm-iommu-v1-sec";
				reg = <0x5000 0x1000>;
				interrupts = <0x0 0x46 0x4>;
			};
		};

		iommu@1f08000 {
			#address-cells = <0x1>;
			#size-cells = <0x1>;
			#iommu-cells = <0x1>;
			compatible = "qcom,msm8916-iommu", "qcom,msm-iommu-v1";
			ranges = <0x0 0x1f08000 0x10000>;
			clocks = <0xd 0x81 0xd 0x8c>;
			clock-names = "iface", "bus";
			qcom,iommu-secure-id = <0x12>;
			phandle = <0x30>;

			iommu-ctx@1000 {
				compatible = "qcom,msm-iommu-v1-ns";
				reg = <0x1000 0x1000>;
				interrupts = <0x0 0xf1 0x4>;
			};

			iommu-ctx@2000 {
				compatible = "qcom,msm-iommu-v1-ns";
				reg = <0x2000 0x1000>;
				interrupts = <0x0 0xf2 0x4>;
			};
		};

		gpu@1c00000 {
			compatible = "qcom,adreno-306.0", "qcom,adreno";
			reg = <0x1c00000 0x20000>;
			reg-names = "kgsl_3d0_reg_memory";
			interrupts = <0x0 0x21 0x4>;
			interrupt-names = "kgsl_3d0_irq";
			clock-names = "core", "iface", "mem", "mem_iface", "alt_mem_iface", "gfx3d";
			clocks = <0xd 0x76 0xd 0x75 0xd 0x69 0xd 0x8e 0xd 0x8f 0xd 0xe>;
			power-domains = <0xd 0x5>;
			operating-points-v2 = <0x2f>;
			iommus = <0x30 0x1 0x30 0x2>;
		};

		mdss@1a00000 {
			compatible = "qcom,mdss";
			reg = <0x1a00000 0x1000 0x1ac8000 0x3000>;
			reg-names = "mdss_phys", "vbif_phys";
			power-domains = <0xd 0x2>;
			clocks = <0xd 0x6d 0xd 0x6e 0xd 0x73>;
			clock-names = "iface", "bus", "vsync";
			interrupts = <0x0 0x48 0x4>;
			interrupt-controller;
			#interrupt-cells = <0x1>;
			#address-cells = <0x1>;
			#size-cells = <0x1>;
			ranges;
			phandle = <0x31>;

			mdp@1a01000 {
				compatible = "qcom,mdp5";
				reg = <0x1a01000 0x89000>;
				reg-names = "mdp_phys";
				interrupt-parent = <0x31>;
				interrupts = <0x0>;
				clocks = <0xd 0x6d 0xd 0x6e 0xd 0x71 0xd 0x73>;
				clock-names = "iface", "bus", "core", "vsync";
				iommus = <0x32 0x4>;
				phandle = <0x94>;

				ports {
					#address-cells = <0x1>;
					#size-cells = <0x0>;

					port@0 {
						reg = <0x0>;

						endpoint {
							remote-endpoint = <0x33>;
							phandle = <0x35>;
						};
					};
				};
			};

			dsi@1a98000 {
				compatible = "qcom,mdss-dsi-ctrl";
				reg = <0x1a98000 0x25c>;
				reg-names = "dsi_ctrl";
				interrupt-parent = <0x31>;
				interrupts = <0x4>;
				assigned-clocks = <0xd 0x2b 0xd 0x2e>;
				assigned-clock-parents = <0x34 0x0 0x34 0x1>;
				clocks = <0xd 0x71 0xd 0x6d 0xd 0x6e 0xd 0x6f 0xd 0x72 0xd 0x70>;
				clock-names = "mdp_core", "iface", "bus", "byte", "pixel", "core";
				phys = <0x34>;
				phy-names = "dsi-phy";
				phandle = <0x95>;

				ports {
					#address-cells = <0x1>;
					#size-cells = <0x0>;

					port@0 {
						reg = <0x0>;

						endpoint {
							remote-endpoint = <0x35>;
							phandle = <0x33>;
						};
					};

					port@1 {
						reg = <0x1>;

						endpoint {
							phandle = <0x96>;
						};
					};
				};
			};

			dsi-phy@1a98300 {
				compatible = "qcom,dsi-phy-28nm-lp";
				reg = <0x1a98300 0xd4 0x1a98500 0x280 0x1a98780 0x30>;
				reg-names = "dsi_pll", "dsi_phy", "dsi_phy_regulator";
				#clock-cells = <0x1>;
				#phy-cells = <0x0>;
				clocks = <0xd 0x6d>;
				clock-names = "iface";
				phandle = <0x34>;
			};
		};

		hexagon@4080000 {
			compatible = "qcom,q6v5-pil";
			reg = <0x4080000 0x100 0x4020000 0x40>;
			reg-names = "qdsp6", "rmb";
			interrupts-extended = <0x1 0x0 0x18 0x1 0x36 0x0 0x0 0x36 0x1 0x0 0x36 0x2 0x0 0x36 0x3 0x0>;
			interrupt-names = "wdog", "fatal", "ready", "handover", "stop-ack";
			clocks = <0xd 0x74 0xd 0xa0 0xd 0x46 0x26>;
			clock-names = "iface", "bus", "mem", "xo";
			qcom,smem-states = <0x37 0x0>;
			qcom,smem-state-names = "stop";
			resets = <0x38 0x0>;
			reset-names = "mss_restart";
			cx-supply = <0x39>;
			mx-supply = <0x3a>;
			pll-supply = <0x3b>;
			qcom,halt-regs = <0xe 0x18000 0x19000 0x1a000>;
			status = "disabled";

			mba {
				memory-region = <0x3c>;
			};

			mpss {
				memory-region = <0x3d>;
			};

			smd-edge {
				interrupts = <0x0 0x19 0x1>;
				qcom,smd-edge = <0x0>;
				qcom,ipc = <0x4 0x8 0xc>;
				qcom,remote-pid = <0x1>;
				label = "hexagon";
			};
		};

		wcnss@a21b000 {
			compatible = "qcom,pronto-v2-pil", "qcom,pronto";
			reg = <0xa204000 0x2000 0xa202000 0x1000 0xa21b000 0x3000>;
			reg-names = "ccu", "dxe", "pmu";
			memory-region = <0x3e>;
			interrupts-extended = <0x1 0x0 0x95 0x1 0x3f 0x0 0x1 0x3f 0x1 0x1 0x3f 0x2 0x1 0x3f 0x3 0x1>;
			interrupt-names = "wdog", "fatal", "ready", "handover", "stop-ack";
			vddmx-supply = <0x3a>;
			vddpx-supply = <0x3b>;
			qcom,state = <0x40 0x0>;
			qcom,state-names = "stop";
			pinctrl-names = "default";
			pinctrl-0 = <0x41>;
			status = "disabled";
			phandle = <0x45>;

			iris {
				compatible = "qcom,wcn3620";
				clocks = <0x42 0x1c>;
				clock-names = "xo";
				vddxo-supply = <0x3b>;
				vddrfa-supply = <0x43>;
				vddpa-supply = <0x44>;
				vdddig-supply = <0x2b>;
			};

			smd-edge {
				interrupts = <0x0 0x8e 0x1>;
				qcom,ipc = <0x4 0x8 0x11>;
				qcom,smd-edge = <0x6>;
				qcom,remote-pid = <0x4>;
				label = "pronto";

				wcnss {
					compatible = "qcom,wcnss";
					qcom,smd-channels = "WCNSS_CTRL";
					qcom,mmio = <0x45>;

					bt {
						compatible = "qcom,wcnss-bt";
					};

					wifi {
						compatible = "qcom,wcnss-wlan";
						interrupts = <0x0 0x91 0x4 0x0 0x92 0x4>;
						interrupt-names = "tx", "rx";
						qcom,smem-states = <0x46 0xa 0x46 0x9>;
						qcom,smem-state-names = "tx-enable", "tx-rings-empty";
					};
				};
			};
		};

		tpiu@820000 {
			compatible = "arm,coresight-tpiu", "arm,primecell";
			reg = <0x820000 0x1000>;
			clocks = <0x42 0x8 0x42 0x9>;
			clock-names = "apb_pclk", "atclk";

			port {

				endpoint {
					slave-mode;
					remote-endpoint = <0x47>;
					phandle = <0x4b>;
				};
			};
		};

		funnel@821000 {
			compatible = "arm,coresight-funnel", "arm,primecell";
			reg = <0x821000 0x1000>;
			clocks = <0x42 0x8 0x42 0x9>;
			clock-names = "apb_pclk", "atclk";

			ports {
				#address-cells = <0x1>;
				#size-cells = <0x0>;

				port@4 {
					reg = <0x4>;

					endpoint {
						slave-mode;
						remote-endpoint = <0x48>;
						phandle = <0x54>;
					};
				};

				port@8 {
					reg = <0x0>;

					endpoint {
						remote-endpoint = <0x49>;
						phandle = <0x4d>;
					};
				};
			};
		};

		replicator@824000 {
			compatible = "arm,coresight-dynamic-replicator", "arm,primecell";
			reg = <0x824000 0x1000>;
			clocks = <0x42 0x8 0x42 0x9>;
			clock-names = "apb_pclk", "atclk";

			ports {
				#address-cells = <0x1>;
				#size-cells = <0x0>;

				port@0 {
					reg = <0x0>;

					endpoint {
						remote-endpoint = <0x4a>;
						phandle = <0x4f>;
					};
				};

				port@1 {
					reg = <0x1>;

					endpoint {
						remote-endpoint = <0x4b>;
						phandle = <0x47>;
					};
				};

				port@2 {
					reg = <0x0>;

					endpoint {
						slave-mode;
						remote-endpoint = <0x4c>;
						phandle = <0x4e>;
					};
				};
			};
		};

		etf@825000 {
			compatible = "arm,coresight-tmc", "arm,primecell";
			reg = <0x825000 0x1000>;
			clocks = <0x42 0x8 0x42 0x9>;
			clock-names = "apb_pclk", "atclk";

			ports {
				#address-cells = <0x1>;
				#size-cells = <0x0>;

				port@0 {
					reg = <0x0>;

					endpoint {
						slave-mode;
						remote-endpoint = <0x4d>;
						phandle = <0x49>;
					};
				};

				port@1 {
					reg = <0x0>;

					endpoint {
						remote-endpoint = <0x4e>;
						phandle = <0x4c>;
					};
				};
			};
		};

		etr@826000 {
			compatible = "arm,coresight-tmc", "arm,primecell";
			reg = <0x826000 0x1000>;
			clocks = <0x42 0x8 0x42 0x9>;
			clock-names = "apb_pclk", "atclk";

			port {

				endpoint {
					slave-mode;
					remote-endpoint = <0x4f>;
					phandle = <0x4a>;
				};
			};
		};

		funnel@841000 {
			compatible = "arm,coresight-funnel", "arm,primecell";
			reg = <0x841000 0x1000>;
			clocks = <0x42 0x8 0x42 0x9>;
			clock-names = "apb_pclk", "atclk";

			ports {
				#address-cells = <0x1>;
				#size-cells = <0x0>;

				port@0 {
					reg = <0x0>;

					endpoint {
						slave-mode;
						remote-endpoint = <0x50>;
						phandle = <0x58>;
					};
				};

				port@1 {
					reg = <0x1>;

					endpoint {
						slave-mode;
						remote-endpoint = <0x51>;
						phandle = <0x59>;
					};
				};

				port@2 {
					reg = <0x2>;

					endpoint {
						slave-mode;
						remote-endpoint = <0x52>;
						phandle = <0x5a>;
					};
				};

				port@3 {
					reg = <0x3>;

					endpoint {
						slave-mode;
						remote-endpoint = <0x53>;
						phandle = <0x5b>;
					};
				};

				port@4 {
					reg = <0x0>;

					endpoint {
						remote-endpoint = <0x54>;
						phandle = <0x48>;
					};
				};
			};
		};

		debug@850000 {
			compatible = "arm,coresight-cpu-debug", "arm,primecell";
			reg = <0x850000 0x1000>;
			clocks = <0x42 0x8>;
			clock-names = "apb_pclk";
			cpu = <0x8>;
		};

		debug@852000 {
			compatible = "arm,coresight-cpu-debug", "arm,primecell";
			reg = <0x852000 0x1000>;
			clocks = <0x42 0x8>;
			clock-names = "apb_pclk";
			cpu = <0x55>;
		};

		debug@854000 {
			compatible = "arm,coresight-cpu-debug", "arm,primecell";
			reg = <0x854000 0x1000>;
			clocks = <0x42 0x8>;
			clock-names = "apb_pclk";
			cpu = <0x56>;
		};

		debug@856000 {
			compatible = "arm,coresight-cpu-debug", "arm,primecell";
			reg = <0x856000 0x1000>;
			clocks = <0x42 0x8>;
			clock-names = "apb_pclk";
			cpu = <0x57>;
		};

		etm@85c000 {
			compatible = "arm,coresight-etm4x", "arm,primecell";
			reg = <0x85c000 0x1000>;
			clocks = <0x42 0x8 0x42 0x9>;
			clock-names = "apb_pclk", "atclk";
			cpu = <0x8>;

			port {

				endpoint {
					remote-endpoint = <0x58>;
					phandle = <0x50>;
				};
			};
		};

		etm@85d000 {
			compatible = "arm,coresight-etm4x", "arm,primecell";
			reg = <0x85d000 0x1000>;
			clocks = <0x42 0x8 0x42 0x9>;
			clock-names = "apb_pclk", "atclk";
			cpu = <0x55>;

			port {

				endpoint {
					remote-endpoint = <0x59>;
					phandle = <0x51>;
				};
			};
		};

		etm@85e000 {
			compatible = "arm,coresight-etm4x", "arm,primecell";
			reg = <0x85e000 0x1000>;
			clocks = <0x42 0x8 0x42 0x9>;
			clock-names = "apb_pclk", "atclk";
			cpu = <0x56>;

			port {

				endpoint {
					remote-endpoint = <0x5a>;
					phandle = <0x52>;
				};
			};
		};

		etm@85f000 {
			compatible = "arm,coresight-etm4x", "arm,primecell";
			reg = <0x85f000 0x1000>;
			clocks = <0x42 0x8 0x42 0x9>;
			clock-names = "apb_pclk", "atclk";
			cpu = <0x57>;

			port {

				endpoint {
					remote-endpoint = <0x5b>;
					phandle = <0x53>;
				};
			};
		};

		video-codec@1d00000 {
			compatible = "qcom,msm8916-venus";
			reg = <0x1d00000 0xff000>;
			interrupts = <0x0 0x2c 0x4>;
			power-domains = <0xd 0x1>;
			clocks = <0xd 0x89 0xd 0x87 0xd 0x88>;
			clock-names = "core", "iface", "bus";
			iommus = <0x32 0x5>;
			memory-region = <0x5c>;
			status = "okay";
			phandle = <0x97>;

			video-decoder {
				compatible = "venus-decoder";
			};

			video-encoder {
				compatible = "venus-encoder";
			};
		};
	};

	smd {
		compatible = "qcom,smd";

		rpm {
			interrupts = <0x0 0xa8 0x1>;
			qcom,ipc = <0x4 0x8 0x0>;
			qcom,smd-edge = <0xf>;

			rpm_requests {
				compatible = "qcom,rpm-msm8916";
				qcom,smd-channels = "rpm_requests";

				qcom,rpmcc {
					compatible = "qcom,rpmcc-msm8916";
					#clock-cells = <0x1>;
					phandle = <0x42>;
				};

				pm8916-regulators {
					compatible = "qcom,rpm-pm8916-regulators";
					phandle = <0x98>;

					s1 {
						phandle = <0x39>;
					};

					s3 {
						phandle = <0x43>;
					};

					s4 {
						phandle = <0x99>;
					};

					l1 {
						phandle = <0x9a>;
					};

					l2 {
						phandle = <0x9b>;
					};

					l3 {
						phandle = <0x3a>;
					};

					l4 {
						phandle = <0x9c>;
					};

					l5 {
						phandle = <0x2b>;
					};

					l6 {
						phandle = <0x9d>;
					};

					l7 {
						phandle = <0x3b>;
					};

					l8 {
						phandle = <0x9e>;
					};

					l9 {
						phandle = <0x44>;
					};

					l10 {
						phandle = <0x9f>;
					};

					l11 {
						phandle = <0xa0>;
					};

					l12 {
						phandle = <0xa1>;
					};

					l13 {
						phandle = <0x2c>;
					};

					l14 {
						phandle = <0xa2>;
					};

					l15 {
						phandle = <0xa3>;
					};

					l16 {
						phandle = <0xa4>;
					};

					l17 {
						phandle = <0xa5>;
					};

					l18 {
						phandle = <0xa6>;
					};
				};
			};
		};
	};

	hexagon-smp2p {
		compatible = "qcom,smp2p";
		qcom,smem = <0x1b3 0x1ac>;
		interrupts = <0x0 0x1b 0x1>;
		qcom,ipc = <0x4 0x8 0xe>;
		qcom,local-pid = <0x0>;
		qcom,remote-pid = <0x1>;

		master-kernel {
			qcom,entry-name = "master-kernel";
			#qcom,smem-state-cells = <0x1>;
			phandle = <0x37>;
		};

		slave-kernel {
			qcom,entry-name = "slave-kernel";
			interrupt-controller;
			#interrupt-cells = <0x2>;
			phandle = <0x36>;
		};
	};

	wcnss-smp2p {
		compatible = "qcom,smp2p";
		qcom,smem = <0x1c3 0x1af>;
		interrupts = <0x0 0x8f 0x1>;
		qcom,ipc = <0x4 0x8 0x12>;
		qcom,local-pid = <0x0>;
		qcom,remote-pid = <0x4>;

		master-kernel {
			qcom,entry-name = "master-kernel";
			#qcom,smem-state-cells = <0x1>;
			phandle = <0x40>;
		};

		slave-kernel {
			qcom,entry-name = "slave-kernel";
			interrupt-controller;
			#interrupt-cells = <0x2>;
			phandle = <0x3f>;
		};
	};

	smsm {
		compatible = "qcom,smsm";
		#address-cells = <0x1>;
		#size-cells = <0x0>;
		qcom,ipc-1 = <0x4 0x8 0xd>;
		qcom,ipc-3 = <0x4 0x8 0x13>;

		apps@0 {
			reg = <0x0>;
			#qcom,smem-state-cells = <0x1>;
			phandle = <0x46>;
		};

		hexagon@1 {
			reg = <0x1>;
			interrupts = <0x0 0x1a 0x1>;
			interrupt-controller;
			#interrupt-cells = <0x2>;
			phandle = <0xa7>;
		};

		wcnss@6 {
			reg = <0x6>;
			interrupts = <0x0 0x90 0x1>;
			interrupt-controller;
			#interrupt-cells = <0x2>;
			phandle = <0xa8>;
		};
	};

	__symbols__ {
		smem_mem = "/reserved-memory/smem_region@86300000";
		mpss_mem = "/reserved-memory/mpss@86800000";
		wcnss_mem = "/reserved-memory/wcnss@89300000";
		venus_mem = "/reserved-memory/venus@89900000";
		mba_mem = "/reserved-memory/mba@8ea00000";
		CPU0 = "/cpus/cpu@0";
		CPU1 = "/cpus/cpu@1";
		CPU2 = "/cpus/cpu@2";
		CPU3 = "/cpus/cpu@3";
		L2_0 = "/cpus/l2-cache";
		CPU_SPC = "/cpus/idle-states/spc";
		cpu_alert0 = "/thermal-zones/cpu-thermal0/trips/trip0";
		cpu_crit0 = "/thermal-zones/cpu-thermal0/trips/trip1";
		cpu_alert1 = "/thermal-zones/cpu-thermal1/trips/trip0";
		cpu_crit1 = "/thermal-zones/cpu-thermal1/trips/trip1";
		cpu_opp_table = "/cpu_opp_table";
		gpu_opp_table = "/opp_table";
		xo_board = "/clocks/xo_board";
		sleep_clk = "/clocks/sleep_clk";
		scm = "/firmware/scm";
		soc = "/soc";
		msmgpio = "/soc/pinctrl@1000000";
		blsp1_uart1_default = "/soc/pinctrl@1000000/blsp1_uart1_default";
		blsp1_uart1_sleep = "/soc/pinctrl@1000000/blsp1_uart1_sleep";
		blsp1_uart2_default = "/soc/pinctrl@1000000/blsp1_uart2_default";
		blsp1_uart2_sleep = "/soc/pinctrl@1000000/blsp1_uart2_sleep";
		spi1_default = "/soc/pinctrl@1000000/spi1_default";
		spi1_sleep = "/soc/pinctrl@1000000/spi1_sleep";
		spi2_default = "/soc/pinctrl@1000000/spi2_default";
		spi2_sleep = "/soc/pinctrl@1000000/spi2_sleep";
		spi3_default = "/soc/pinctrl@1000000/spi3_default";
		spi3_sleep = "/soc/pinctrl@1000000/spi3_sleep";
		spi4_default = "/soc/pinctrl@1000000/spi4_default";
		spi4_sleep = "/soc/pinctrl@1000000/spi4_sleep";
		spi5_default = "/soc/pinctrl@1000000/spi5_default";
		spi5_sleep = "/soc/pinctrl@1000000/spi5_sleep";
		spi6_default = "/soc/pinctrl@1000000/spi6_default";
		spi6_sleep = "/soc/pinctrl@1000000/spi6_sleep";
		i2c2_default = "/soc/pinctrl@1000000/i2c2_default";
		i2c2_sleep = "/soc/pinctrl@1000000/i2c2_sleep";
		i2c4_default = "/soc/pinctrl@1000000/i2c4_default";
		i2c4_sleep = "/soc/pinctrl@1000000/i2c4_sleep";
		i2c6_default = "/soc/pinctrl@1000000/i2c6_default";
		i2c6_sleep = "/soc/pinctrl@1000000/i2c6_sleep";
		sdc1_clk_on = "/soc/pinctrl@1000000/pmx_sdc1_clk/clk_on";
		sdc1_clk_off = "/soc/pinctrl@1000000/pmx_sdc1_clk/clk_off";
		sdc1_cmd_on = "/soc/pinctrl@1000000/pmx_sdc1_cmd/cmd_on";
		sdc1_cmd_off = "/soc/pinctrl@1000000/pmx_sdc1_cmd/cmd_off";
		sdc1_data_on = "/soc/pinctrl@1000000/pmx_sdc1_data/data_on";
		sdc1_data_off = "/soc/pinctrl@1000000/pmx_sdc1_data/data_off";
		sdc2_clk_on = "/soc/pinctrl@1000000/pmx_sdc2_clk/clk_on";
		sdc2_clk_off = "/soc/pinctrl@1000000/pmx_sdc2_clk/clk_off";
		sdc2_cmd_on = "/soc/pinctrl@1000000/pmx_sdc2_cmd/cmd_on";
		sdc2_cmd_off = "/soc/pinctrl@1000000/pmx_sdc2_cmd/cmd_off";
		sdc2_data_on = "/soc/pinctrl@1000000/pmx_sdc2_data/data_on";
		sdc2_data_off = "/soc/pinctrl@1000000/pmx_sdc2_data/data_off";
		sdc2_cd_on = "/soc/pinctrl@1000000/pmx_sdc2_cd_pin/cd_on";
		sdc2_cd_off = "/soc/pinctrl@1000000/pmx_sdc2_cd_pin/cd_off";
		cdc_pdm_lines_act = "/soc/pinctrl@1000000/cdc-pdm-lines/pdm_lines_on";
		cdc_pdm_lines_sus = "/soc/pinctrl@1000000/cdc-pdm-lines/pdm_lines_off";
		ext_pri_tlmm_lines_act = "/soc/pinctrl@1000000/ext-pri-tlmm-lines/ext_pa_on";
		ext_pri_tlmm_lines_sus = "/soc/pinctrl@1000000/ext-pri-tlmm-lines/ext_pa_off";
		ext_pri_ws_act = "/soc/pinctrl@1000000/ext-pri-ws-line/ext_pa_on";
		ext_pri_ws_sus = "/soc/pinctrl@1000000/ext-pri-ws-line/ext_pa_off";
		ext_mclk_tlmm_lines_act = "/soc/pinctrl@1000000/ext-mclk-tlmm-lines/mclk_lines_on";
		ext_mclk_tlmm_lines_sus = "/soc/pinctrl@1000000/ext-mclk-tlmm-lines/mclk_lines_off";
		ext_sec_tlmm_lines_act = "/soc/pinctrl@1000000/ext-sec-tlmm-lines/tlmm_lines_on";
		ext_sec_tlmm_lines_sus = "/soc/pinctrl@1000000/ext-sec-tlmm-lines/tlmm_lines_off";
		cdc_dmic_lines_act = "/soc/pinctrl@1000000/cdc-dmic-lines/dmic_lines_on";
		cdc_dmic_lines_sus = "/soc/pinctrl@1000000/cdc-dmic-lines/dmic_lines_off";
		wcnss_pin_a = "/soc/pinctrl@1000000/wcnss-active";
		gcc = "/soc/clock-controller@1800000";
		tcsr_mutex_regs = "/soc/syscon@1905000";
		tcsr = "/soc/syscon@1937000";
		tcsr_mutex = "/soc/hwlock";
		rpm_msg_ram = "/soc/memory@60000";
		blsp1_uart1 = "/soc/serial@78af000";
		a53pll = "/soc/clock@b016000";
		apcs = "/soc/mailbox@b011000";
		blsp1_uart2 = "/soc/serial@78b0000";
		blsp_dma = "/soc/dma@7884000";
		blsp_spi1 = "/soc/spi@78b5000";
		blsp_spi2 = "/soc/spi@78b6000";
		blsp_spi3 = "/soc/spi@78b7000";
		blsp_spi4 = "/soc/spi@78b8000";
		blsp_spi5 = "/soc/spi@78b9000";
		blsp_spi6 = "/soc/spi@78ba000";
		blsp_i2c2 = "/soc/i2c@78b6000";
		blsp_i2c4 = "/soc/i2c@78b8000";
		blsp_i2c6 = "/soc/i2c@78ba000";
		lpass = "/soc/lpass@7708000";
		lpass_codec = "/soc/codec";
		sdhc_1 = "/soc/sdhci@7824000";
		sdhc_2 = "/soc/sdhci@7864000";
		otg = "/soc/usb@78d9000";
		usb_hs_phy = "/soc/usb@78d9000/ulpi/phy";
		intc = "/soc/interrupt-controller@b000000";
		spmi_bus = "/soc/spmi@200f000";
		pm8916_0 = "/soc/spmi@200f000/pm8916@0";
		pm8916_gpios = "/soc/spmi@200f000/pm8916@0/gpios@c000";
		pm8916_mpps = "/soc/spmi@200f000/pm8916@0/mpps@a000";
		pm8916_temp = "/soc/spmi@200f000/pm8916@0/temp-alarm@2400";
		pm8916_vadc = "/soc/spmi@200f000/pm8916@0/vadc@3100";
		pm8916_1 = "/soc/spmi@200f000/pm8916@1";
		wcd_codec = "/soc/spmi@200f000/pm8916@1/codec@f000";
		qfprom = "/soc/qfprom@5c000";
		tsens_caldata = "/soc/qfprom@5c000/caldata@d0";
		tsens_calsel = "/soc/qfprom@5c000/calsel@ec";
		tsens = "/soc/thermal-sensor@4a8000";
		apps_iommu = "/soc/iommu@1ef0000";
		gpu_iommu = "/soc/iommu@1f08000";
		mdss = "/soc/mdss@1a00000";
		mdp = "/soc/mdss@1a00000/mdp@1a01000";
		mdp5_intf1_out = "/soc/mdss@1a00000/mdp@1a01000/ports/port@0/endpoint";
		dsi0 = "/soc/mdss@1a00000/dsi@1a98000";
		dsi0_in = "/soc/mdss@1a00000/dsi@1a98000/ports/port@0/endpoint";
		dsi0_out = "/soc/mdss@1a00000/dsi@1a98000/ports/port@1/endpoint";
		dsi_phy0 = "/soc/mdss@1a00000/dsi-phy@1a98300";
		pronto = "/soc/wcnss@a21b000";
		tpiu_in = "/soc/tpiu@820000/port/endpoint";
		funnel0_in4 = "/soc/funnel@821000/ports/port@4/endpoint";
		funnel0_out = "/soc/funnel@821000/ports/port@8/endpoint";
		replicator_out0 = "/soc/replicator@824000/ports/port@0/endpoint";
		replicator_out1 = "/soc/replicator@824000/ports/port@1/endpoint";
		replicator_in = "/soc/replicator@824000/ports/port@2/endpoint";
		etf_in = "/soc/etf@825000/ports/port@0/endpoint";
		etf_out = "/soc/etf@825000/ports/port@1/endpoint";
		etr_in = "/soc/etr@826000/port/endpoint";
		funnel1_in0 = "/soc/funnel@841000/ports/port@0/endpoint";
		funnel1_in1 = "/soc/funnel@841000/ports/port@1/endpoint";
		funnel1_in2 = "/soc/funnel@841000/ports/port@2/endpoint";
		funnel1_in3 = "/soc/funnel@841000/ports/port@3/endpoint";
		funnel1_out = "/soc/funnel@841000/ports/port@4/endpoint";
		etm0_out = "/soc/etm@85c000/port/endpoint";
		etm1_out = "/soc/etm@85d000/port/endpoint";
		etm2_out = "/soc/etm@85e000/port/endpoint";
		etm3_out = "/soc/etm@85f000/port/endpoint";
		venus = "/soc/video-codec@1d00000";
		rpmcc = "/smd/rpm/rpm_requests/qcom,rpmcc";
		smd_rpm_regulators = "/smd/rpm/rpm_requests/pm8916-regulators";
		pm8916_s1 = "/smd/rpm/rpm_requests/pm8916-regulators/s1";
		pm8916_s3 = "/smd/rpm/rpm_requests/pm8916-regulators/s3";
		pm8916_s4 = "/smd/rpm/rpm_requests/pm8916-regulators/s4";
		pm8916_l1 = "/smd/rpm/rpm_requests/pm8916-regulators/l1";
		pm8916_l2 = "/smd/rpm/rpm_requests/pm8916-regulators/l2";
		pm8916_l3 = "/smd/rpm/rpm_requests/pm8916-regulators/l3";
		pm8916_l4 = "/smd/rpm/rpm_requests/pm8916-regulators/l4";
		pm8916_l5 = "/smd/rpm/rpm_requests/pm8916-regulators/l5";
		pm8916_l6 = "/smd/rpm/rpm_requests/pm8916-regulators/l6";
		pm8916_l7 = "/smd/rpm/rpm_requests/pm8916-regulators/l7";
		pm8916_l8 = "/smd/rpm/rpm_requests/pm8916-regulators/l8";
		pm8916_l9 = "/smd/rpm/rpm_requests/pm8916-regulators/l9";
		pm8916_l10 = "/smd/rpm/rpm_requests/pm8916-regulators/l10";
		pm8916_l11 = "/smd/rpm/rpm_requests/pm8916-regulators/l11";
		pm8916_l12 = "/smd/rpm/rpm_requests/pm8916-regulators/l12";
		pm8916_l13 = "/smd/rpm/rpm_requests/pm8916-regulators/l13";
		pm8916_l14 = "/smd/rpm/rpm_requests/pm8916-regulators/l14";
		pm8916_l15 = "/smd/rpm/rpm_requests/pm8916-regulators/l15";
		pm8916_l16 = "/smd/rpm/rpm_requests/pm8916-regulators/l16";
		pm8916_l17 = "/smd/rpm/rpm_requests/pm8916-regulators/l17";
		pm8916_l18 = "/smd/rpm/rpm_requests/pm8916-regulators/l18";
		hexagon_smp2p_out = "/hexagon-smp2p/master-kernel";
		hexagon_smp2p_in = "/hexagon-smp2p/slave-kernel";
		wcnss_smp2p_out = "/wcnss-smp2p/master-kernel";
		wcnss_smp2p_in = "/wcnss-smp2p/slave-kernel";
		apps_smsm = "/smsm/apps@0";
		hexagon_smsm = "/smsm/hexagon@1";
		wcnss_smsm = "/smsm/wcnss@6";
	};
};
